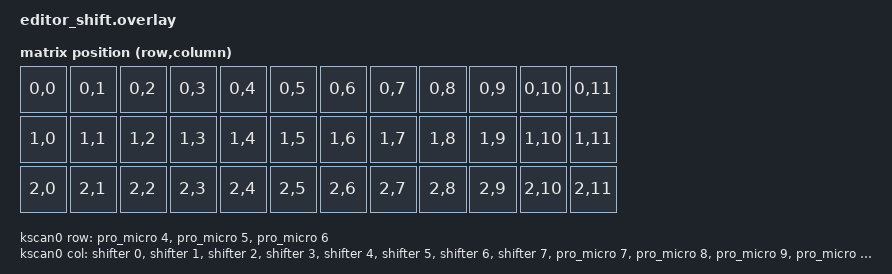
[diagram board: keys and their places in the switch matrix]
/* Generated by ZMK Editor from editor_shift.editor.json. */

#include <dt-bindings/zmk/matrix_transform.h>
#include <physical_layouts.dtsi>

/ {
    chosen {
        zmk,kscan = &kscan0;
        zmk,physical-layout = &editor_shift_layout;
    };

    kscan0: kscan {
        compatible = "zmk,kscan-gpio-matrix";
        wakeup-source;
        diode-direction = "col2row";

        row-gpios
            = <&pro_micro  4 (GPIO_ACTIVE_HIGH | GPIO_PULL_DOWN)>
            , <&pro_micro  5 (GPIO_ACTIVE_HIGH | GPIO_PULL_DOWN)>
            , <&pro_micro  6 (GPIO_ACTIVE_HIGH | GPIO_PULL_DOWN)>
            ;

        col-gpios
            = <&shifter  0 GPIO_ACTIVE_HIGH>
            , <&shifter  1 GPIO_ACTIVE_HIGH>
            , <&shifter  2 GPIO_ACTIVE_HIGH>
            , <&shifter  3 GPIO_ACTIVE_HIGH>
            , <&shifter  4 GPIO_ACTIVE_HIGH>
            , <&shifter  5 GPIO_ACTIVE_HIGH>
            , <&shifter  6 GPIO_ACTIVE_HIGH>
            , <&shifter  7 GPIO_ACTIVE_HIGH>
            , <&pro_micro  7 GPIO_ACTIVE_HIGH>
            , <&pro_micro  8 GPIO_ACTIVE_HIGH>
            , <&pro_micro  9 GPIO_ACTIVE_HIGH>
            , <&pro_micro 10 GPIO_ACTIVE_HIGH>
            ;
    };

    default_transform: keymap_transform_0 {
        compatible = "zmk,matrix-transform";
        rows = <3>;
        columns = <12>;
        map = <
RC(0,0)  RC(0,1)  RC(0,2)  RC(0,3)  RC(0,4)  RC(0,5)  RC(0,6)  RC(0,7)  RC(0,8)  RC(0,9)  RC(0,10) RC(0,11)
RC(1,0)  RC(1,1)  RC(1,2)  RC(1,3)  RC(1,4)  RC(1,5)  RC(1,6)  RC(1,7)  RC(1,8)  RC(1,9)  RC(1,10) RC(1,11)
RC(2,0)  RC(2,1)  RC(2,2)  RC(2,3)  RC(2,4)  RC(2,5)  RC(2,6)  RC(2,7)  RC(2,8)  RC(2,9)  RC(2,10) RC(2,11)
        >;
    };

    editor_shift_layout: editor_shift_layout {
        compatible = "zmk,physical-layout";
        display-name = "Editor Shift";
        transform = <&default_transform>;

        keys  //                     w   h    x    y     rot   rx   ry
            = <&key_physical_attrs 100 100    0    0      0    0    0>
            , <&key_physical_attrs 100 100  100    0      0    0    0>
            , <&key_physical_attrs 100 100  200    0      0    0    0>
            , <&key_physical_attrs 100 100  300    0      0    0    0>
            , <&key_physical_attrs 100 100  400    0      0    0    0>
            , <&key_physical_attrs 100 100  500    0      0    0    0>
            , <&key_physical_attrs 100 100  600    0      0    0    0>
            , <&key_physical_attrs 100 100  700    0      0    0    0>
            , <&key_physical_attrs 100 100  800    0      0    0    0>
            , <&key_physical_attrs 100 100  900    0      0    0    0>
            , <&key_physical_attrs 100 100 1000    0      0    0    0>
            , <&key_physical_attrs 100 100 1100    0      0    0    0>
            , <&key_physical_attrs 100 100    0  100      0    0    0>
            , <&key_physical_attrs 100 100  100  100      0    0    0>
            , <&key_physical_attrs 100 100  200  100      0    0    0>
            , <&key_physical_attrs 100 100  300  100      0    0    0>
            , <&key_physical_attrs 100 100  400  100      0    0    0>
            , <&key_physical_attrs 100 100  500  100      0    0    0>
            , <&key_physical_attrs 100 100  600  100      0    0    0>
            , <&key_physical_attrs 100 100  700  100      0    0    0>
            , <&key_physical_attrs 100 100  800  100      0    0    0>
            , <&key_physical_attrs 100 100  900  100      0    0    0>
            , <&key_physical_attrs 100 100 1000  100      0    0    0>
            , <&key_physical_attrs 100 100 1100  100      0    0    0>
            , <&key_physical_attrs 100 100    0  200      0    0    0>
            , <&key_physical_attrs 100 100  100  200      0    0    0>
            , <&key_physical_attrs 100 100  200  200      0    0    0>
            , <&key_physical_attrs 100 100  300  200      0    0    0>
            , <&key_physical_attrs 100 100  400  200      0    0    0>
            , <&key_physical_attrs 100 100  500  200      0    0    0>
            , <&key_physical_attrs 100 100  600  200      0    0    0>
            , <&key_physical_attrs 100 100  700  200      0    0    0>
            , <&key_physical_attrs 100 100  800  200      0    0    0>
            , <&key_physical_attrs 100 100  900  200      0    0    0>
            , <&key_physical_attrs 100 100 1000  200      0    0    0>
            , <&key_physical_attrs 100 100 1100  200      0    0    0>
            ;
    };
};

&pinctrl {
    shift_register_spi_default: shift_register_spi_default {
        group1 {
            psels = <NRF_PSEL(SPIM_SCK, 0, 20)>,
                <NRF_PSEL(SPIM_MOSI, 0, 17)>;
        };
    };
    shift_register_spi_sleep: shift_register_spi_sleep {
        group1 {
            psels = <NRF_PSEL(SPIM_SCK, 0, 20)>,
                <NRF_PSEL(SPIM_MOSI, 0, 17)>;
            low-power-enable;
        };
    };
};

&spi2 {
    status = "okay";
    compatible = "nordic,nrf-spim";
    pinctrl-0 = <&shift_register_spi_default>;
    pinctrl-1 = <&shift_register_spi_sleep>;
    pinctrl-names = "default", "sleep";
    cs-gpios = <&pro_micro 21 GPIO_ACTIVE_LOW>;

    shifter: 595@0 {
        compatible = "zmk,gpio-595";
        status = "okay";
        gpio-controller;
        spi-max-frequency = <1000000>;
        reg = <0>;
        #gpio-cells = <2>;
        ngpios = <8>;
    };
};
